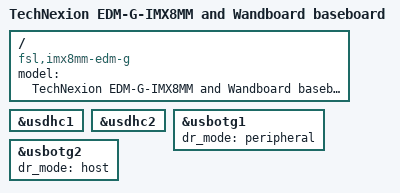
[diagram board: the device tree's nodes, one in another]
/*
 * Copyright 2020 Technexion Ltd.
 * 
 * Author: Richard Hu <Richard.hu@technexion.com>
 *
 * This program is free software; you can redistribute it and/or
 * modify it under the terms of the GNU General Public License
 * as published by the Free Software Foundation; either version 2
 * of the License, or (at your option) any later version.
 *
 * This program is distributed in the hope that it will be useful,
 * but WITHOUT ANY WARRANTY; without even the implied warranty of
 * MERCHANTABILITY or FITNESS FOR A PARTICULAR PURPOSE.  See the
 * GNU General Public License for more details.
 */

/dts-v1/;

#include "imx8mm-edm-g.dtsi"

/ {
	model = "TechNexion EDM-G-IMX8MM and Wandboard baseboard";
	compatible = "fsl,imx8mm-edm-g", "fsl,imx8mm";
};

&usdhc1 {
	status = "okay";
};

&usdhc2 {
	status = "okay";
};

&usbotg1 {
	dr_mode = "peripheral";
	status = "okay";
};

&usbotg2 {
	dr_mode = "host";
	status = "okay";
};
